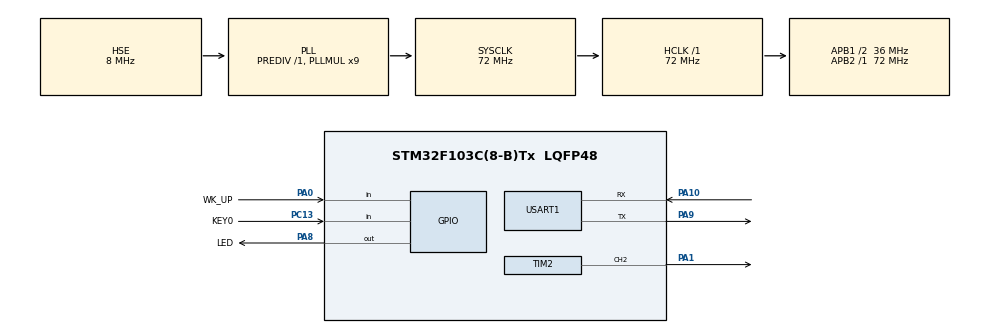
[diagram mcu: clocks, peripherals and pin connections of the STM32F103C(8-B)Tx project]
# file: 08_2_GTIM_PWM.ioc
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Mcu.Family=STM32F1
Mcu.Name=STM32F103C(8-B)Tx
Mcu.Package=LQFP48
NVIC.PriorityGroup=NVIC_PRIORITYGROUP_2
NVIC.USART1_IRQn=true\:2\:0\:true\:false\:true\:true\:true\:true
PA0-WKUP.GPIO_Label=WK_UP
PA0-WKUP.GPIO_PuPd=GPIO_PULLDOWN
PA0-WKUP.Signal=GPIO_Input
PA1.Signal=S_TIM2_CH2
PA10.Mode=Asynchronous
PA10.Signal=USART1_RX
PA13.Mode=Serial_Wire
PA13.Signal=SYS_JTMS-SWDIO
PA14.Mode=Serial_Wire
PA14.Signal=SYS_JTCK-SWCLK
PA8.GPIO_Label=LED
PA8.GPIO_PuPd=GPIO_PULLUP
PA8.GPIO_Speed=GPIO_SPEED_FREQ_HIGH
PA8.PinState=GPIO_PIN_RESET
PA8.Signal=GPIO_Output
PA9.Mode=Asynchronous
PA9.Signal=USART1_TX
PC13-TAMPER-RTC.GPIO_Label=KEY0
PC13-TAMPER-RTC.GPIO_PuPd=GPIO_PULLUP
PC13-TAMPER-RTC.Signal=GPIO_Input
PC14-OSC32_IN.Mode=LSE-External-Oscillator
PC14-OSC32_IN.Signal=RCC_OSC32_IN
PC15-OSC32_OUT.Mode=LSE-External-Oscillator
PC15-OSC32_OUT.Signal=RCC_OSC32_OUT
PD0-OSC_IN.Mode=HSE-External-Oscillator
PD0-OSC_IN.Signal=RCC_OSC_IN
PD1-OSC_OUT.Mode=HSE-External-Oscillator
PD1-OSC_OUT.Signal=RCC_OSC_OUT
ProjectManager.HeapSize=0x200
ProjectManager.StackSize=0x400
ProjectManager.TargetToolchain=STM32CubeIDE
RCC.AHBFreq_Value=72000000
RCC.APB1CLKDivider=RCC_HCLK_DIV2
RCC.APB1Freq_Value=36000000
RCC.APB1TimFreq_Value=72000000
RCC.APB2Freq_Value=72000000
RCC.APB2TimFreq_Value=72000000
RCC.HCLKFreq_Value=72000000
RCC.PLLMUL=RCC_PLL_MUL9
RCC.PLLSourceVirtual=RCC_PLLSOURCE_HSE
RCC.SYSCLKFreq_VALUE=72000000
RCC.SYSCLKSource=RCC_SYSCLKSOURCE_PLLCLK
RCC.USBFreq_Value=72000000
SH.S_TIM2_CH2.0=TIM2_CH2,PWM Generation2 CH2
TIM2.AutoReloadPreload=TIM_AUTORELOAD_PRELOAD_ENABLE
TIM2.Channel-PWM\ Generation2\ CH2=TIM_CHANNEL_2
TIM2.OCPolarity_2=TIM_OCPOLARITY_LOW
TIM2.Period=500 - 1
TIM2.Prescaler=72 - 1
TIM2.Pulse-PWM\ Generation2\ CH2=250
USART1.VirtualMode=VM_ASYNC
VP_TIM2_VS_ClockSourceINT.Mode=Internal
board=custom

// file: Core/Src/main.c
/**
 ****************************************************************************************************
 * @file        main.c
 * @author      ALIENTEK
 * @brief       General-purpose timers PWM output code
 * @license     Copyright (C) 2020-2032, ALIENTEK
 ****************************************************************************************************
 * @attention
 *
 * platform  	: ALIENTEK STM32F103 development board
 * website		: https://www.alientek.com
 * forum		: http://www.openedv.com/forum.php
 *
 * change logs	:
 * version		data		notes
 * V1.0			20240222	the first version
 *
 ****************************************************************************************************
 */

/* USER CODE BEGIN Header */

/* USER CODE END Header */
#include "main.h"
#include "tim.h"
#include "usart.h"
#include "gpio.h"

/* USER CODE BEGIN Includes */
#include "../../BSP/LED/led.h"
#include "../../BSP/KEY/key.h"
/* USER CODE END Includes */

void SystemClock_Config(void);

int main(void)
{
  /* USER CODE BEGIN 1 */
	uint8_t dir = 1;
	uint32_t ledrpwmval = 0;
  /* USER CODE END 1 */

  /* MCU Configuration--------------------------------------------------------*/

  /* Reset of all peripherals, Initializes the Flash interface and the Systick. */
  HAL_Init();

  /* Configure the system clock */
  SystemClock_Config();

  /* Initialize all configured peripherals */
  MX_GPIO_Init();
  MX_USART1_UART_Init();
  MX_TIM2_Init();

  /* Infinite loop */
  /* USER CODE BEGIN WHILE */
  while (1)
  {
	  HAL_Delay(10);	/* delay 10ms */

	  if (dir == 1)
	  {
		  ledrpwmval++;	/* dir == 1, ledrpwmval increments */
	  }
	  else
	  {
		  ledrpwmval--;	/* dir == 0, ledrpwmval decrements */
	  }

	  if (ledrpwmval > 300)
	  {
		  dir = 0;		/* After ledrpwmval reaches 300, the direction is decreasing */
	  }

	  if (ledrpwmval == 0)
	  {
		  dir = 1;		/* After ledrpwmval decrements to 0, the direction is changed to increasing */
	  }

	  /* Modify the comparison value to control the duty cycle */
	  __HAL_TIM_SET_COMPARE(&htim2, TIM_CHANNEL_2, ledrpwmval);
    /* USER CODE END WHILE */

  }
}

void SystemClock_Config(void)
{
  RCC_OscInitTypeDef RCC_OscInitStruct = {0};
  RCC_ClkInitTypeDef RCC_ClkInitStruct = {0};

  /** Initializes the RCC Oscillators according to the specified parameters
  * in the RCC_OscInitTypeDef structure.
  */
  RCC_OscInitStruct.OscillatorType = RCC_OSCILLATORTYPE_HSE;
  RCC_OscInitStruct.HSEState = RCC_HSE_ON;
  RCC_OscInitStruct.HSEPredivValue = RCC_HSE_PREDIV_DIV1;
  RCC_OscInitStruct.HSIState = RCC_HSI_ON;
  RCC_OscInitStruct.PLL.PLLState = RCC_PLL_ON;
  RCC_OscInitStruct.PLL.PLLSource = RCC_PLLSOURCE_HSE;
  RCC_OscInitStruct.PLL.PLLMUL = RCC_PLL_MUL9;
  if (HAL_RCC_OscConfig(&RCC_OscInitStruct) != HAL_OK)
  {
    Error_Handler();
  }

  /** Initializes the CPU, AHB and APB buses clocks
  */
  RCC_ClkInitStruct.ClockType = RCC_CLOCKTYPE_HCLK|RCC_CLOCKTYPE_SYSCLK
                              |RCC_CLOCKTYPE_PCLK1|RCC_CLOCKTYPE_PCLK2;
  RCC_ClkInitStruct.SYSCLKSource = RCC_SYSCLKSOURCE_PLLCLK;
  RCC_ClkInitStruct.AHBCLKDivider = RCC_SYSCLK_DIV1;
  RCC_ClkInitStruct.APB1CLKDivider = RCC_HCLK_DIV2;
  RCC_ClkInitStruct.APB2CLKDivider = RCC_HCLK_DIV1;

  if (HAL_RCC_ClockConfig(&RCC_ClkInitStruct, FLASH_LATENCY_2) != HAL_OK)
  {
    Error_Handler();
  }
}

void Error_Handler(void)
{
  __disable_irq();
  while (1)
  {
  }
}
